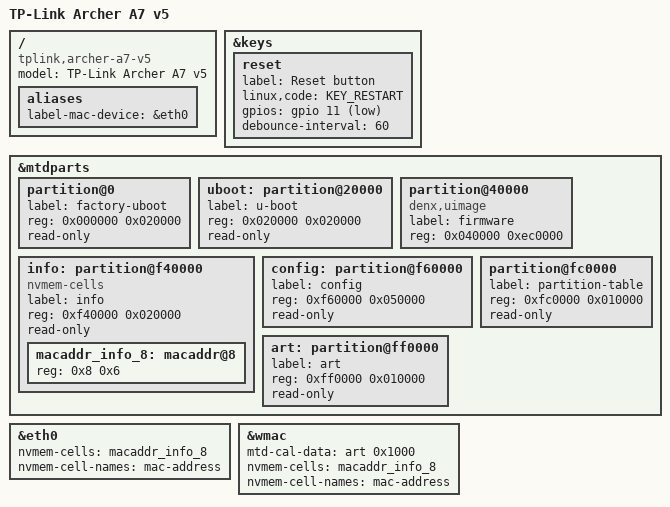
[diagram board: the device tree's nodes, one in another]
// SPDX-License-Identifier: GPL-2.0-or-later OR MIT

#include "qca9563_tplink_archer-x7-v5.dtsi"

/ {
	compatible = "tplink,archer-a7-v5", "qca,qca9563";
	model = "TP-Link Archer A7 v5";

	aliases {
		label-mac-device = &eth0;
	};
};

&keys {
	reset {
		label = "Reset button";
		linux,code = <KEY_RESTART>;
		gpios = <&gpio 11 GPIO_ACTIVE_LOW>;
		debounce-interval = <60>;
	};
};

&mtdparts {
	partition@0 {
		label = "factory-uboot";
		reg = <0x000000 0x020000>;
		read-only;
	};

	uboot: partition@20000 {
		label = "u-boot";
		reg = <0x020000 0x020000>;
		read-only;
	};

	partition@40000 {
		label = "firmware";
		reg = <0x040000 0xec0000>;
		compatible = "denx,uimage";
	};

	info: partition@f40000 {
		label = "info";
		reg = <0xf40000 0x020000>;
		read-only;
	};

	config: partition@f60000 {
		label = "config";
		reg = <0xf60000 0x050000>;
		read-only;
	};

	partition@fc0000 {
		label = "partition-table";
		reg = <0xfc0000 0x010000>;
		read-only;
	};

	art: partition@ff0000 {
		label = "art";
		reg = <0xff0000 0x010000>;
		read-only;
	};
};

&eth0 {
	nvmem-cells = <&macaddr_info_8>;
	nvmem-cell-names = "mac-address";
};

&wmac {
	mtd-cal-data = <&art 0x1000>;

	nvmem-cells = <&macaddr_info_8>;
	nvmem-cell-names = "mac-address";
};

&info {
	compatible = "nvmem-cells";
	#address-cells = <1>;
	#size-cells = <1>;

	macaddr_info_8: macaddr@8 {
		reg = <0x8 0x6>;
	};
};
